# CY8C3246PVI_147 register map
File version: 0.1
Registers are 8-bit, read-write, no defined reset value unless marked. A register's access mark holds for its fields unless they carry their own. Offsets are from the block's base; [hi:lo] are bit positions; 'fields as' and 'values as' point back to an identical list.

## CW_Hold_Control
Base 0x00000000
0x657B CW_Hold_Control_CONTROL_REG

## I2S
Base 0x00000000
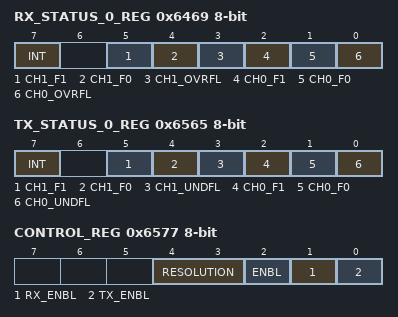
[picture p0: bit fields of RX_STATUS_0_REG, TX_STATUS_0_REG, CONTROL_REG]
0x6469 RX_STATUS_0_REG
  [7] INT ro — Interrupt bit
  [5] CH1_F1 ro — Stereo channel 1 FIFO 1 state
    0=EMPTY; 1=NOT_EMPTY
  [4] CH1_F0 ro — Stereo channel 1 FIFO 0 state
    0=EMPTY; 1=NOT_EMPTY
  [3] CH1_OVRFL ro — Stereo channel 1 FIFO overflow
    0=NO_OVERFLOW; 1=OVERFLOW
  [2] CH0_F1 ro — Stereo channel 0 FIFO 1 state
    0=EMPTY; 1=NOT_EMPTY
  [1] CH0_F0 ro — Stereo channel 0 FIFO 0 state
    0=EMPTY; 1=NOT_EMPTY
  [0] CH0_OVRFL ro — Stereo channel 0 FIFO overflow
    0=NO_OVERFLOW; 1=OVERFLOW
0x6565 TX_STATUS_0_REG
  [7] INT ro — Interrupt bit
  [5] CH1_F1 ro — Stereo channel 1 FIFO 1 state
    0=FULL; 1=NOT_FULL
  [4] CH1_F0 ro — Stereo channel 1 FIFO 0 state
    0=FULL; 1=NOT_FULL
  [3] CH1_UNDFL ro — Stereo channel 1 FIFO underflow
    0=NO_UNDERFLOW; 1=UNDERFLOW
  [2] CH0_F1 ro — Stereo channel 0 FIFO 1 state
    0=FULL; 1=NOT_FULL
  [1] CH0_F0 ro — Stereo channel 0 FIFO 0 state
    0=FULL; 1=NOT_FULL
  [0] CH0_UNDFL ro — Stereo channel 0 FIFO underflow
    0=NO_UNDERFLOW; 1=UNDERFLOW
0x6577 CONTROL_REG
  [4:3] RESOLUTION — Specifies data bits value. Applicable only if dynamic bit resolution is selected.
    0=Cy8_BIT; 1=Cy16_BIT; 2=Cy24_BIT; 3=Cy32_BIT
  [2] ENBL — Starts the generation of the WS and SCK outputs.
    1=ENABLED; 0=DISABLED
  [1] RX_ENBL — Enables Rx direction. Applicable only if Rx direction presents for the component.
    1=ENABLED; 0=DISABLED
  [0] TX_ENBL — Enables Tx direction. Applicable only if Tx direction presents for the component.
    1=ENABLED; 0=DISABLED

## USBFS_EP17_DMA_Done_SR
Base 0x00000000; alternate view of USBFS
0x6566 USBFS_EP17_DMA_Done_SR_STATUS_REG
0x6586 USBFS_EP17_DMA_Done_SR_MASK_REG
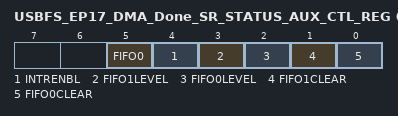
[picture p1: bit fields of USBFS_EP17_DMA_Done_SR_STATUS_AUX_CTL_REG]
0x6596 USBFS_EP17_DMA_Done_SR_STATUS_AUX_CTL_REG
  [5] FIFO0 — FIFO0 clear
    1=ENABLED (Enable counter); 0=DISABLED (Disable counter)
  [4] INTRENBL — Enables or disables the Interrupt
    1=ENABLED (Interrupt enabled); 0=DISABLED (Interrupt disabled)
  [3] FIFO1LEVEL — FIFO level
    1=ENABLED (FIFO LVL: input mode: FIFO at least 1/2 empty; output mode: FIFO at least 1/2 full); 0=DISABLED (FIFO LVL: input mode: FIFO not full; output mode: FIFO not empty)
  [2] FIFO0LEVEL — FIFO level
    values as FIFO1LEVEL
  [1] FIFO1CLEAR — FIFO clear
    1=ENABLED (Clear FIFO state); 0=DISABLED (Normal FIFO operation)
  [0] FIFO0CLEAR — FIFO clear
    values as FIFO1CLEAR

## USBFS_EP8_DMA_Done_SR
Base 0x00000000; alternate view of USBFS
0x656A USBFS_EP8_DMA_Done_SR_STATUS_REG
0x658A USBFS_EP8_DMA_Done_SR_MASK_REG
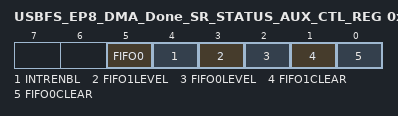
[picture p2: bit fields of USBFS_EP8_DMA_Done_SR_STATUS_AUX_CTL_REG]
0x659A USBFS_EP8_DMA_Done_SR_STATUS_AUX_CTL_REG
  [5] FIFO0 — FIFO0 clear
    1=ENABLED (Enable counter); 0=DISABLED (Disable counter)
  [4] INTRENBL — Enables or disables the Interrupt
    1=ENABLED (Interrupt enabled); 0=DISABLED (Interrupt disabled)
  [3] FIFO1LEVEL — FIFO level
    1=ENABLED (FIFO LVL: input mode: FIFO at least 1/2 empty; output mode: FIFO at least 1/2 full); 0=DISABLED (FIFO LVL: input mode: FIFO not full; output mode: FIFO not empty)
  [2] FIFO0LEVEL — FIFO level
    values as FIFO1LEVEL
  [1] FIFO1CLEAR — FIFO clear
    1=ENABLED (Clear FIFO state); 0=DISABLED (Normal FIFO operation)
  [0] FIFO0CLEAR — FIFO clear
    values as FIFO1CLEAR

## Control
Base 0x00000000
0x6479 Control_CONTROL_REG

## Status
Base 0x00000000
0x6464 Status_STATUS_REG
0x6484 Status_MASK_REG
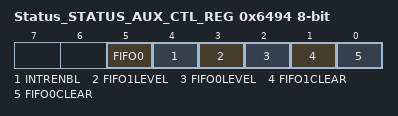
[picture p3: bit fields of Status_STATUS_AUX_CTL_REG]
0x6494 Status_STATUS_AUX_CTL_REG
  [5] FIFO0 — FIFO0 clear
    1=ENABLED (Enable counter); 0=DISABLED (Disable counter)
  [4] INTRENBL — Enables or disables the Interrupt
    1=ENABLED (Interrupt enabled); 0=DISABLED (Interrupt disabled)
  [3] FIFO1LEVEL — FIFO level
    1=ENABLED (FIFO LVL: input mode: FIFO at least 1/2 empty; output mode: FIFO at least 1/2 full); 0=DISABLED (FIFO LVL: input mode: FIFO not full; output mode: FIFO not empty)
  [2] FIFO0LEVEL — FIFO level
    values as FIFO1LEVEL
  [1] FIFO1CLEAR — FIFO clear
    1=ENABLED (Clear FIFO state); 0=DISABLED (Normal FIFO operation)
  [0] FIFO0CLEAR — FIFO clear
    values as FIFO1CLEAR
